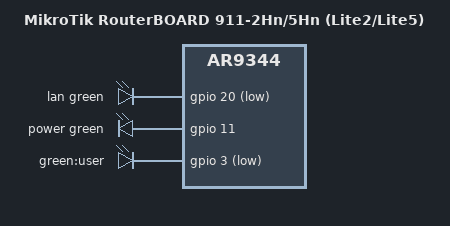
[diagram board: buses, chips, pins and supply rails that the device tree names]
// SPDX-License-Identifier: GPL-2.0-or-later OR MIT

#include <dt-bindings/leds/common.h>

#include "ar9344_mikrotik_routerboard.dtsi"
#include "ar9344_mikrotik_routerboard-16m-nor.dtsi"

/ {
	model = "MikroTik RouterBOARD 911-2Hn/5Hn (Lite2/Lite5)";
	compatible = "mikrotik,routerboard-911-lite", "qca,ar9344";
};

&leds {
	pinctrl-names = "default";
	pinctrl-0 = <&enable_gpio_20>;

	lan {
		function = LED_FUNCTION_LAN;
		color = <LED_COLOR_ID_GREEN>;
		gpios = <&gpio 20 GPIO_ACTIVE_LOW>;
	};

	power {
		function = LED_FUNCTION_POWER;
		color = <LED_COLOR_ID_GREEN>;
		gpios = <&gpio 11 GPIO_ACTIVE_HIGH>;
		default-state = "on";
	};

	led_user: user {
		label = "green:user";
		gpios = <&gpio 3 (GPIO_ACTIVE_LOW|GPIO_OPEN_DRAIN)>;
	};
};

&pinmux {
	enable_gpio_20: pinmux_gpio_out_function5 {
		pinctrl-single,bits = <0x14 0x0 0xff>;
	};
};
